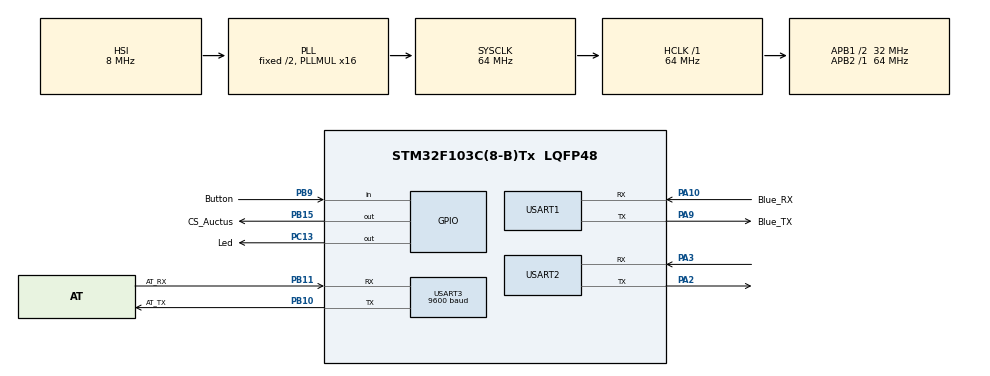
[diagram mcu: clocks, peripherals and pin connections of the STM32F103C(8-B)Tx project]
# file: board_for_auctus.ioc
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Mcu.Family=STM32F1
Mcu.Name=STM32F103C(8-B)Tx
Mcu.Package=LQFP48
NVIC.PriorityGroup=NVIC_PRIORITYGROUP_4
PA10.GPIO_Label=Blue_RX
PA10.Mode=Asynchronous
PA10.Signal=USART1_RX
PA13.Mode=Serial_Wire
PA13.Signal=SYS_JTMS-SWDIO
PA14.Mode=Serial_Wire
PA14.Signal=SYS_JTCK-SWCLK
PA2.Mode=Asynchronous
PA2.Signal=USART2_TX
PA3.Mode=Asynchronous
PA3.Signal=USART2_RX
PA9.GPIO_Label=Blue_TX
PA9.Mode=Asynchronous
PA9.Signal=USART1_TX
PB10.GPIO_Label=AT_TX
PB10.Mode=Asynchronous
PB10.Signal=USART3_TX
PB11.GPIO_Label=AT_RX
PB11.Mode=Asynchronous
PB11.Signal=USART3_RX
PB15.GPIO_Label=CS_Auctus
PB15.Signal=GPIO_Output
PB9.GPIO_Label=Button
PB9.Signal=GPIO_Input
PC13-TAMPER-RTC.GPIO_Label=Led
PC13-TAMPER-RTC.Signal=GPIO_Output
ProjectManager.HeapSize=0x200
ProjectManager.StackSize=0x400
ProjectManager.TargetToolchain=STM32CubeIDE
RCC.AHBFreq_Value=64000000
RCC.APB1CLKDivider=RCC_HCLK_DIV2
RCC.APB1Freq_Value=32000000
RCC.APB1TimFreq_Value=64000000
RCC.APB2Freq_Value=64000000
RCC.APB2TimFreq_Value=64000000
RCC.HCLKFreq_Value=64000000
RCC.PLLMUL=RCC_PLL_MUL16
RCC.SYSCLKFreq_VALUE=64000000
RCC.SYSCLKSource=RCC_SYSCLKSOURCE_PLLCLK
RCC.USBFreq_Value=64000000
USART1.VirtualMode=VM_ASYNC
USART2.VirtualMode=VM_ASYNC
USART3.BaudRate=9600
USART3.VirtualMode=VM_ASYNC
board=custom

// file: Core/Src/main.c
/* USER CODE BEGIN Header */
/**
  ******************************************************************************
  * @file           : main.c
  * @brief          : Main program body
  ******************************************************************************
  * @attention
  *
  * Copyright (c) 2023 STMicroelectronics.
  * All rights reserved.
  *
  * This software is licensed under terms that can be found in the LICENSE file
  * in the root directory of this software component.
  * If no LICENSE file comes with this software, it is provided AS-IS.
  *
  ******************************************************************************
  */
/* USER CODE END Header */
#include "main.h"
#include "usart.h"
#include "gpio.h"

/* USER CODE BEGIN Includes */
#include "auctus.h"

/* USER CODE END Includes */

void SystemClock_Config(void);
/* USER CODE BEGIN PFP */
void Simple_auctus_setup(int volume, int addr);

/* USER CODE END PFP */

int main(void)
{

  /* MCU Configuration--------------------------------------------------------*/

  /* Reset of all peripherals, Initializes the Flash interface and the Systick. */
  HAL_Init();

  /* Configure the system clock */
  SystemClock_Config();

  /* Initialize all configured peripherals */
  MX_GPIO_Init();
  MX_USART1_UART_Init();
  MX_USART2_UART_Init();
  MX_USART3_UART_Init();

  /* Infinite loop */
  /* USER CODE BEGIN WHILE */
    uint8_t state = 0;

    /*
     * Логика такая - сначала сбрасываем модуль импульсом 1сек потом ждем 1 сек что бы он запустился
     * но по хорошему надо не ждать время а ждать ответ по юарт +DMOGETSTARTUP:1 - означает что модуль включился
     * после этого уже начинать общение и после каждой команды ждать обратную связь от модуля и парсить ответы
     * также ногой PA12 надо управлять MUTE состоянием и при передачи данных что бы не создавать наводки
     */

    HAL_GPIO_WritePin(CS_Auctus_GPIO_Port, CS_Auctus_Pin, 1);
    HAL_Delay(1000);
    HAL_GPIO_WritePin(Led_GPIO_Port, Led_Pin, 0);
    HAL_Delay(1000);

    state = simple_setup_auctus(&huart3, 18, 16700000, 1, 423125000, 423125000);
    HAL_GPIO_WritePin(CS_Auctus_GPIO_Port, CS_Auctus_Pin, 0);

    while (1)
  {
    /* USER CODE END WHILE */

    /* USER CODE BEGIN 3 */
    if(state == 0){
        HAL_GPIO_TogglePin(Led_GPIO_Port, Led_Pin);
        HAL_Delay(1000);
    }

  }
  /* USER CODE END 3 */
}

void SystemClock_Config(void)
{
  RCC_OscInitTypeDef RCC_OscInitStruct = {0};
  RCC_ClkInitTypeDef RCC_ClkInitStruct = {0};

  /** Initializes the RCC Oscillators according to the specified parameters
  * in the RCC_OscInitTypeDef structure.
  */
  RCC_OscInitStruct.OscillatorType = RCC_OSCILLATORTYPE_HSI;
  RCC_OscInitStruct.HSIState = RCC_HSI_ON;
  RCC_OscInitStruct.HSICalibrationValue = RCC_HSICALIBRATION_DEFAULT;
  RCC_OscInitStruct.PLL.PLLState = RCC_PLL_ON;
  RCC_OscInitStruct.PLL.PLLSource = RCC_PLLSOURCE_HSI_DIV2;
  RCC_OscInitStruct.PLL.PLLMUL = RCC_PLL_MUL16;
  if (HAL_RCC_OscConfig(&RCC_OscInitStruct) != HAL_OK)
  {
    Error_Handler();
  }

  /** Initializes the CPU, AHB and APB buses clocks
  */
  RCC_ClkInitStruct.ClockType = RCC_CLOCKTYPE_HCLK|RCC_CLOCKTYPE_SYSCLK
                              |RCC_CLOCKTYPE_PCLK1|RCC_CLOCKTYPE_PCLK2;
  RCC_ClkInitStruct.SYSCLKSource = RCC_SYSCLKSOURCE_PLLCLK;
  RCC_ClkInitStruct.AHBCLKDivider = RCC_SYSCLK_DIV1;
  RCC_ClkInitStruct.APB1CLKDivider = RCC_HCLK_DIV2;
  RCC_ClkInitStruct.APB2CLKDivider = RCC_HCLK_DIV1;

  if (HAL_RCC_ClockConfig(&RCC_ClkInitStruct, FLASH_LATENCY_2) != HAL_OK)
  {
    Error_Handler();
  }
}

void Error_Handler(void)
{
  __disable_irq();
  while (1)
  {
  }
}
